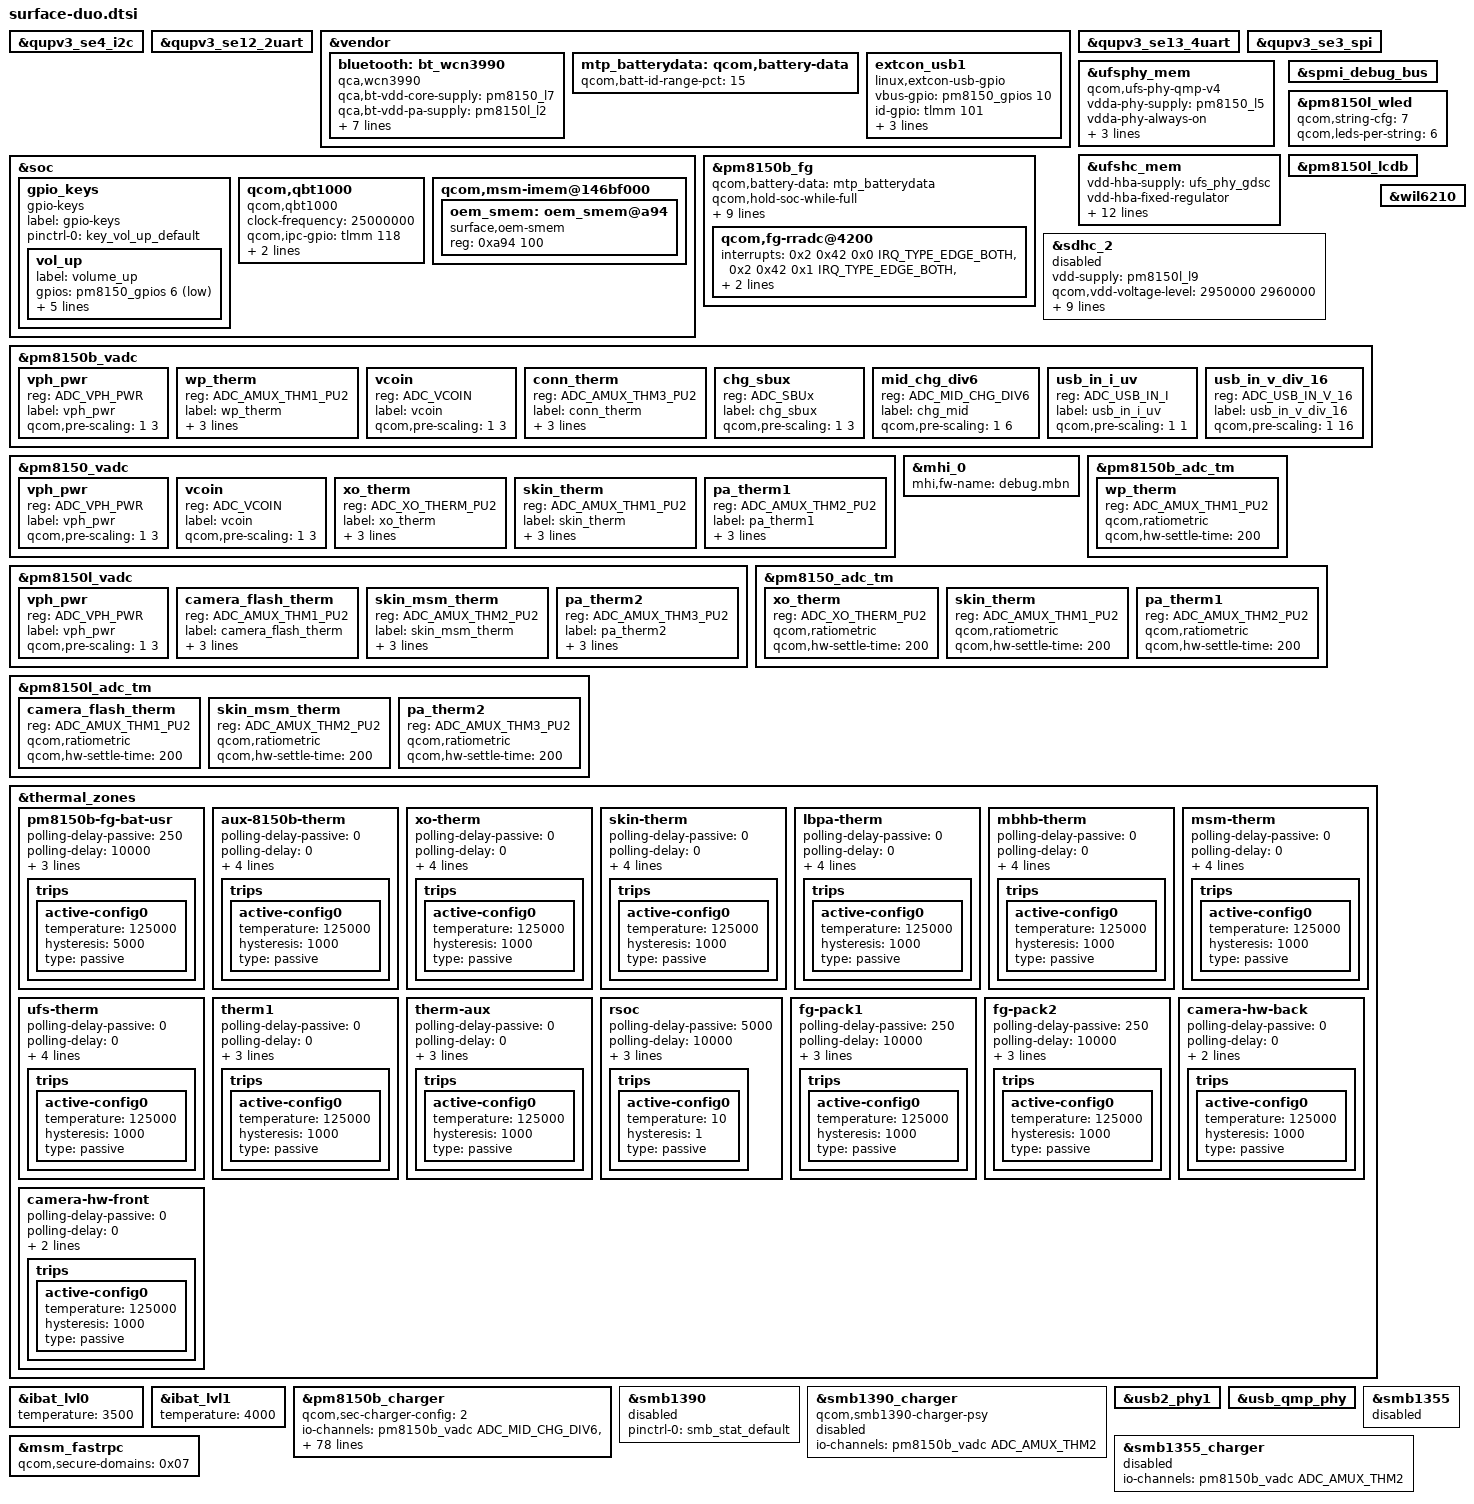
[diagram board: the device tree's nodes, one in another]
/*
 * Copyright (c) 2020 Microsoft Corporation
 *
 * This program is free software; you can redistribute it and/or modify it
 * under the terms of the GNU General Public License version 2 as published by
 * the Free Software Foundation.
 */

#include <dt-bindings/gpio/gpio.h>
#include <dt-bindings/input/input.h>

#include "../qcom/sm8150-pmic-overlay.dtsi"
//#include "../qcom/sm8150-sde-display.dtsi"
#include "surface-duo-display.dtsi"
#include "../qcom/sm8150-thermal-overlay.dtsi"
#include "surface-duo-audio.dtsi"
#include "surface-duo-usb.dtsi"
#include "surface-duo-fpc.dtsi"
#include "surface-duo-touch.dtsi"
#include "surface-duo-fuelgauge.dtsi"
#include "surface-duo-camera-sensor.dtsi"
//#include "surface-duo-powermonitors.dtsi"
#include "da7280.dtsi"
#include "surface-duo-smb138x.dtsi"
#include "surface-duo-pmic-overlay.dtsi"
#include "surface-duo-surface.dtsi"

&qupv3_se4_i2c {
#address-cells = <1>;
#size-cells = <0>;

#include "../qcom/smb1390.dtsi"
#include "../qcom/smb1355.dtsi"
};

&qupv3_se12_2uart {
	status = "ok";
};

&vendor {
	bluetooth: bt_wcn3990 {
		compatible = "qca,wcn3990";
		qca,bt-vdd-core-supply = <&pm8150_l7>;
		qca,bt-vdd-pa-supply = <&pm8150l_l2>;
		qca,bt-vdd-ldo-supply = <&pm8150l_l11>;

		qca,bt-vdd-core-voltage-level = <1800000 1800000>;
		qca,bt-vdd-pa-voltage-level = <1304000 1304000>;
		qca,bt-vdd-ldo-voltage-level = <3312000 3312000>;

		qca,bt-vdd-core-current-level = <0>; /* LPM/PFM */
		qca,bt-vdd-pa-current-level = <0>; /* LPM/PFM */
		qca,bt-vdd-ldo-current-level = <0>; /* LPM/PFM */
	};

	mtp_batterydata: qcom,battery-data {
		qcom,batt-id-range-pct = <15>;
		#include "../qcom/fg-gen4-batterydata-alium-3600mah.dtsi"
	};

	extcon_usb1: extcon_usb1 {
		compatible = "linux,extcon-usb-gpio";
		vbus-gpio = <&pm8150_gpios 10 GPIO_ACTIVE_HIGH>;
		id-gpio = <&tlmm 101 GPIO_ACTIVE_HIGH>;
		vbus-out-gpio = <&pm8150_gpios 9 GPIO_ACTIVE_HIGH>;

		pinctrl-names = "default";
		pinctrl-0 = <&usb2_vbus_det_default
			     &usb2_id_det_default
			     &usb2_vbus_boost_default>;
	};
};

&qupv3_se13_4uart {
	status = "ok";
};

&qupv3_se3_spi {
	status = "ok";
};

&qupv3_se4_i2c {
	status = "ok";
};

&soc {
	gpio_keys {
		compatible = "gpio-keys";
		label = "gpio-keys";

		pinctrl-names = "default";
		pinctrl-0 = <&key_vol_up_default>;

		vol_up {
			label = "volume_up";
			gpios = <&pm8150_gpios 6 GPIO_ACTIVE_LOW>;
			linux,input-type = <1>;
			linux,code = <KEY_VOLUMEUP>;
			gpio-key,wakeup;
			debounce-interval = <15>;
			linux,can-disable;
		};
	};

	qcom,qbt1000 {
		compatible = "qcom,qbt1000";
		clock-names = "core", "iface";
		clock-frequency = <25000000>;
		qcom,ipc-gpio = <&tlmm 118 0>;
		pinctrl-names = "default";
		pinctrl-0 = <&key_home_default>;
		qcom,finger-detect-gpio = <&pm8150_gpios 1 0>;
	};

	qcom,msm-imem@146bf000 {
		oem_smem: oem_smem@a94 {
			compatible = "surface,oem-smem";
			reg = <0xa94 100>;
		};
	};
};
/*
&dsi_sharp_4k_dsc_cmd {
	qcom,panel-supply-entries = <&dsi_panel_pwr_supply>;
	qcom,mdss-dsi-bl-pmic-control-type = "bl_ctrl_wled";
	qcom,mdss-dsi-bl-min-level = <1>;
	qcom,mdss-dsi-bl-max-level = <4095>;
	qcom,mdss-dsi-mode-sel-gpio-state = "dual_port";
	qcom,panel-mode-gpio = <&tlmm 7 0>;
	qcom,platform-te-gpio = <&tlmm 8 0>;
	qcom,platform-reset-gpio = <&tlmm 6 0>;
};

&dsi_sharp_4k_dsc_video {
	qcom,panel-supply-entries = <&dsi_panel_pwr_supply>;
	qcom,mdss-dsi-bl-pmic-control-type = "bl_ctrl_wled";
	qcom,mdss-dsi-bl-min-level = <1>;
	qcom,mdss-dsi-bl-max-level = <4095>;
	qcom,mdss-dsi-mode-sel-gpio-state = "dual_port";
	qcom,panel-mode-gpio = <&tlmm 7 0>;
	qcom,platform-te-gpio = <&tlmm 8 0>;
	qcom,platform-reset-gpio = <&tlmm 6 0>;
};

&dsi_sim_cmd {
	qcom,panel-supply-entries = <&dsi_panel_pwr_supply>;
	qcom,mdss-dsi-bl-pmic-control-type = "bl_ctrl_dcs";
	qcom,platform-reset-gpio = <&tlmm 6 0>;
};

&dsi_sim_vid {
	qcom,panel-supply-entries = <&dsi_panel_pwr_supply>;
	qcom,mdss-dsi-bl-pmic-control-type = "bl_ctrl_dcs";
	qcom,platform-reset-gpio = <&tlmm 6 0>;
};

&dsi_dual_sim_cmd {
	qcom,panel-supply-entries = <&dsi_panel_pwr_supply>;
	qcom,mdss-dsi-bl-pmic-control-type = "bl_ctrl_dcs";
	qcom,platform-reset-gpio = <&tlmm 6 0>;
};

&dsi_dual_sim_vid {
	qcom,panel-supply-entries = <&dsi_panel_pwr_supply>;
	qcom,mdss-dsi-bl-pmic-control-type = "bl_ctrl_dcs";
	qcom,platform-reset-gpio = <&tlmm 6 0>;
};

&dsi_sim_sec_hd_cmd {
	qcom,panel-supply-entries = <&dsi_panel_pwr_supply>;
	qcom,panel-sec-supply-entries = <&dsi_panel_pwr_supply_vdd_no_labibb>;
	qcom,mdss-dsi-bl-pmic-control-type = "bl_ctrl_wled";
	qcom,mdss-dsi-bl-min-level = <1>;
	qcom,mdss-dsi-bl-max-level = <4095>;
	qcom,mdss-dsi-mode-sel-gpio-state = "single_port";
	qcom,panel-mode-gpio = <&tlmm 7 0>;
	qcom,platform-reset-gpio = <&tlmm 6 0>;
	qcom,panel-sec-mode-gpio = <&tlmm 77 0>;
	qcom,platform-sec-reset-gpio = <&tlmm 66 0>;
};

&dsi_dual_nt35597_truly_video {
	qcom,panel-supply-entries = <&dsi_panel_pwr_supply>;
	qcom,mdss-dsi-bl-pmic-control-type = "bl_ctrl_wled";
	qcom,mdss-dsi-bl-min-level = <1>;
	qcom,mdss-dsi-bl-max-level = <4095>;
	qcom,mdss-dsi-mode-sel-gpio-state = "dual_port";
	qcom,panel-mode-gpio = <&tlmm 7 0>;
	qcom,platform-te-gpio = <&tlmm 8 0>;
	qcom,platform-reset-gpio = <&tlmm 6 0>;
};

&dsi_dual_nt35597_truly_cmd {
	qcom,panel-supply-entries = <&dsi_panel_pwr_supply>;
	qcom,mdss-dsi-bl-pmic-control-type = "bl_ctrl_wled";
	qcom,mdss-dsi-bl-min-level = <1>;
	qcom,mdss-dsi-bl-max-level = <4095>;
	qcom,mdss-dsi-mode-sel-gpio-state = "dual_port";
	qcom,panel-mode-gpio = <&tlmm 7 0>;
	qcom,platform-te-gpio = <&tlmm 8 0>;
	qcom,platform-reset-gpio = <&tlmm 6 0>;
};

&dsi_sim_dsc_375_cmd {
	qcom,panel-supply-entries = <&dsi_panel_pwr_supply>;
	qcom,mdss-dsi-bl-pmic-control-type = "bl_ctrl_dcs";
	qcom,platform-reset-gpio = <&tlmm 6 0>;
};

&dsi_dual_sim_dsc_375_cmd {
	qcom,panel-supply-entries = <&dsi_panel_pwr_supply>;
	qcom,mdss-dsi-bl-pmic-control-type = "bl_ctrl_dcs";
	qcom,platform-reset-gpio = <&tlmm 6 0>;
};

&dsi_nt35597_truly_dsc_cmd {
	qcom,panel-supply-entries = <&dsi_panel_pwr_supply>;
	qcom,mdss-dsi-bl-pmic-control-type = "bl_ctrl_wled";
	qcom,mdss-dsi-bl-min-level = <1>;
	qcom,mdss-dsi-bl-max-level = <4095>;
	qcom,mdss-dsi-mode-sel-gpio-state = "single_port";
	qcom,panel-mode-gpio = <&tlmm 7 0>;
	qcom,platform-te-gpio = <&tlmm 8 0>;
	qcom,platform-reset-gpio = <&tlmm 6 0>;
};

&dsi_nt35597_truly_dsc_video {
	qcom,panel-supply-entries = <&dsi_panel_pwr_supply>;
	qcom,mdss-dsi-bl-pmic-control-type = "bl_ctrl_wled";
	qcom,mdss-dsi-bl-min-level = <1>;
	qcom,mdss-dsi-bl-max-level = <4095>;
	qcom,mdss-dsi-mode-sel-gpio-state = "single_port";
	qcom,panel-mode-gpio = <&tlmm 7 0>;
	qcom,platform-te-gpio = <&tlmm 8 0>;
	qcom,platform-reset-gpio = <&tlmm 6 0>;
};

&dsi_nt35695b_truly_fhd_cmd {
	qcom,panel-supply-entries = <&dsi_panel_pwr_supply>;
	qcom,mdss-dsi-bl-pmic-control-type = "bl_ctrl_wled";
	qcom,mdss-dsi-bl-min-level = <1>;
	qcom,mdss-dsi-bl-max-level = <4095>;
	qcom,mdss-dsi-mode-sel-gpio-state = "single_port";
	qcom,panel-mode-gpio = <&tlmm 7 0>;
	qcom,platform-te-gpio = <&tlmm 8 0>;
	qcom,platform-reset-gpio = <&tlmm 6 0>;
};

&dsi_nt35695b_truly_fhd_video {
	qcom,panel-supply-entries = <&dsi_panel_pwr_supply>;
	qcom,mdss-dsi-bl-pmic-control-type = "bl_ctrl_wled";
	qcom,mdss-dsi-bl-min-level = <1>;
	qcom,mdss-dsi-bl-max-level = <4095>;
	qcom,mdss-dsi-mode-sel-gpio-state = "single_port";
	qcom,panel-mode-gpio = <&tlmm 7 0>;
	qcom,platform-te-gpio = <&tlmm 8 0>;
	qcom,platform-reset-gpio = <&tlmm 6 0>;
};*/

&ufsphy_mem {
	compatible = "qcom,ufs-phy-qmp-v4";

	vdda-phy-supply = <&pm8150_l5>;
	vdda-phy-always-on;
	vdda-pll-supply = <&pm8150l_l3>;
	vdda-phy-max-microamp = <90200>;
	vdda-pll-max-microamp = <19000>;

	status = "ok";
};

&ufshc_mem {
	vdd-hba-supply = <&ufs_phy_gdsc>;
	vdd-hba-fixed-regulator;
	vcc-supply = <&pm8150_l10>;
	vcc-voltage-level = <2504000 2950000>;
	vcc-low-voltage-sup;
	vccq-supply = <&pm8150_l9>;
	vccq2-supply = <&pm8150_s4>;
	vcc-max-microamp = <750000>;
	vccq-max-microamp = <700000>;
	vccq2-max-microamp = <750000>;

	qcom,vddp-ref-clk-supply = <&pm8150_l9>;
	qcom,vddp-ref-clk-max-microamp = <100>;
	qcom,vccq-parent-supply = <&pm8150l_s8>;
	qcom,vccq-parent-max-microamp = <210000>;

	status = "ok";
};

&spmi_debug_bus {
	status = "ok";
};

&pm8150l_wled {
	qcom,string-cfg= <7>;
	qcom,leds-per-string = <6>;
	status = "ok";
};

&pm8150l_lcdb {
	status = "ok";
};

&pm8150b_fg {
	qcom,battery-data = <&mtp_batterydata>;
	qcom,hold-soc-while-full;
	qcom,linearize-soc;
	qcom,five-pin-battery;
	qcom,cl-wt-enable;
	/* ESR fast calibration */
	qcom,fg-esr-timer-chg-fast = <0 7>;
	qcom,fg-esr-timer-dischg-fast = <0 7>;
	qcom,fg-esr-timer-chg-slow = <0 96>;
	qcom,fg-esr-timer-dischg-slow = <0 96>;
	qcom,fg-esr-cal-soc-thresh = <26 230>;
	qcom,fg-esr-cal-temp-thresh = <10 40>;

	qcom,fg-rradc@4200 {
		/* Disable Batt-Temp-delta Interrupt */
		interrupts = <0x2 0x42 0x0 IRQ_TYPE_EDGE_BOTH>,
			     <0x2 0x42 0x1 IRQ_TYPE_EDGE_BOTH>,
			     <0x2 0x42 0x3 IRQ_TYPE_EDGE_BOTH>,
			     <0x2 0x42 0x4 IRQ_TYPE_EDGE_BOTH>;
		interrupt-names = "batt-missing",
				  "batt-id",
				  "batt-temp-hot",
				  "batt-temp-cold";
	};
};

&sdhc_2 {
	vdd-supply = <&pm8150l_l9>;
	qcom,vdd-voltage-level = <2950000 2960000>;
	qcom,vdd-current-level = <200 800000>;

	vdd-io-supply = <&pm8150l_l6>;
	qcom,vdd-io-voltage-level = <1808000 2960000>;
	qcom,vdd-io-current-level = <200 22000>;

	pinctrl-names = "active", "sleep";
	pinctrl-0 = <&sdc2_clk_on  &sdc2_cmd_on &sdc2_data_on &storage_cd>;
	pinctrl-1 = <&sdc2_clk_off &sdc2_cmd_off &sdc2_data_off &storage_cd>;

	cd-gpios = <&tlmm 96 GPIO_ACTIVE_LOW>;

	status = "disabled";
};

&pm8150b_vadc {
	vph_pwr {
		reg = <ADC_VPH_PWR>;
		label = "vph_pwr";
		qcom,pre-scaling = <1 3>;
	};

	wp_therm {
		reg = <ADC_AMUX_THM1_PU2>;
		label = "wp_therm";
		qcom,ratiometric;
		qcom,hw-settle-time = <200>;
		qcom,pre-scaling = <1 1>;
	};

	vcoin {
		reg = <ADC_VCOIN>;
		label = "vcoin";
		qcom,pre-scaling = <1 3>;
	};

	conn_therm {
		reg = <ADC_AMUX_THM3_PU2>;
		label = "conn_therm";
		qcom,ratiometric;
		qcom,hw-settle-time = <200>;
		qcom,pre-scaling = <1 1>;
	};

	chg_sbux {
		reg = <ADC_SBUx>;
		label = "chg_sbux";
		qcom,pre-scaling = <1 3>;
	};

	mid_chg_div6 {
		reg = <ADC_MID_CHG_DIV6>;
		label = "chg_mid";
		qcom,pre-scaling = <1 6>;
	};

	usb_in_i_uv {
		reg = <ADC_USB_IN_I>;
		label = "usb_in_i_uv";
		qcom,pre-scaling = <1 1>;
	};

	usb_in_v_div_16 {
		reg = <ADC_USB_IN_V_16>;
		label = "usb_in_v_div_16";
		qcom,pre-scaling = <1 16>;
	};
};

&pm8150_vadc {
	vph_pwr {
		reg = <ADC_VPH_PWR>;
		label = "vph_pwr";
		qcom,pre-scaling = <1 3>;
	};

	vcoin {
		reg = <ADC_VCOIN>;
		label = "vcoin";
		qcom,pre-scaling = <1 3>;
	};

	xo_therm {
		reg = <ADC_XO_THERM_PU2>;
		label = "xo_therm";
		qcom,ratiometric;
		qcom,hw-settle-time = <200>;
		qcom,pre-scaling = <1 1>;
	};

	skin_therm {
		reg = <ADC_AMUX_THM1_PU2>;
		label = "skin_therm";
		qcom,ratiometric;
		qcom,hw-settle-time = <200>;
		qcom,pre-scaling = <1 1>;
	};

	pa_therm1 {
		reg = <ADC_AMUX_THM2_PU2>;
		label = "pa_therm1";
		qcom,ratiometric;
		qcom,hw-settle-time = <200>;
		qcom,pre-scaling = <1 1>;
	};
};

&pm8150l_vadc {
	vph_pwr {
		reg = <ADC_VPH_PWR>;
		label = "vph_pwr";
		qcom,pre-scaling = <1 3>;
	};

	camera_flash_therm {
		reg = <ADC_AMUX_THM1_PU2>;
		label = "camera_flash_therm";
		qcom,ratiometric;
		qcom,hw-settle-time = <200>;
		qcom,pre-scaling = <1 1>;
	};

	skin_msm_therm {
		reg = <ADC_AMUX_THM2_PU2>;
		label = "skin_msm_therm";
		qcom,ratiometric;
		qcom,hw-settle-time = <200>;
		qcom,pre-scaling = <1 1>;
	};

	pa_therm2 {
		reg = <ADC_AMUX_THM3_PU2>;
		label = "pa_therm2";
		qcom,ratiometric;
		qcom,hw-settle-time = <200>;
		qcom,pre-scaling = <1 1>;
	};
};

&wil6210 {
	status = "ok";
};

&mhi_0 {
	mhi,fw-name = "debug.mbn";
};

&pm8150b_adc_tm {
	wp_therm {
		reg = <ADC_AMUX_THM1_PU2>;
		qcom,ratiometric;
		qcom,hw-settle-time = <200>;
	};
};

&pm8150_adc_tm {
	xo_therm {
		reg = <ADC_XO_THERM_PU2>;
		qcom,ratiometric;
		qcom,hw-settle-time = <200>;
	};

	skin_therm {
		reg = <ADC_AMUX_THM1_PU2>;
		qcom,ratiometric;
		qcom,hw-settle-time = <200>;
	};

	pa_therm1 {
		reg = <ADC_AMUX_THM2_PU2>;
		qcom,ratiometric;
		qcom,hw-settle-time = <200>;
	};
};

&pm8150l_adc_tm {
	camera_flash_therm {
		reg = <ADC_AMUX_THM1_PU2>;
		qcom,ratiometric;
		qcom,hw-settle-time = <200>;
	};

	skin_msm_therm {
		reg = <ADC_AMUX_THM2_PU2>;
		qcom,ratiometric;
		qcom,hw-settle-time = <200>;
	};

	pa_therm2 {
		reg = <ADC_AMUX_THM3_PU2>;
		qcom,ratiometric;
		qcom,hw-settle-time = <200>;
	};
};

&thermal_zones {
	pm8150b-fg-bat-usr {
		polling-delay-passive = <250>;
		polling-delay = <10000>;
		thermal-governor = "user_space";
		thermal-sensors = <&pm8150b_fg>;
		wake-capable-sensor;

		trips {
			active-config0 {
				temperature = <125000>;
				hysteresis = <5000>;
				type = "passive";
			};
		};
	};

	aux-8150b-therm {
		polling-delay-passive = <0>;
		polling-delay = <0>;
		thermal-governor = "user_space";
		thermal-sensors = <&pm8150b_adc_tm ADC_AMUX_THM1_PU2>;
		wake-capable-sensor;
		trips {
			active-config0 {
				temperature = <125000>;
				hysteresis = <1000>;
				type = "passive";
			};
		};
	};

	xo-therm {
		polling-delay-passive = <0>;
		polling-delay = <0>;
		thermal-governor = "user_space";
		thermal-sensors = <&pm8150_adc_tm ADC_XO_THERM_PU2>;
		wake-capable-sensor;
		trips {
			active-config0 {
				temperature = <125000>;
				hysteresis = <1000>;
				type = "passive";
			};
		};
	};

	skin-therm {
		polling-delay-passive = <0>;
		polling-delay = <0>;
		thermal-governor = "user_space";
		thermal-sensors = <&pm8150_adc_tm ADC_AMUX_THM1_PU2>;
		wake-capable-sensor;
		trips {
			active-config0 {
				temperature = <125000>;
				hysteresis = <1000>;
				type = "passive";
			};
		};
	};

	lbpa-therm {
		polling-delay-passive = <0>;
		polling-delay = <0>;
		thermal-governor = "user_space";
		thermal-sensors = <&pm8150_adc_tm ADC_AMUX_THM2_PU2>;
		wake-capable-sensor;
		trips {
			active-config0 {
				temperature = <125000>;
				hysteresis = <1000>;
				type = "passive";
			};
		};
	};

	mbhb-therm {
		polling-delay-passive = <0>;
		polling-delay = <0>;
		thermal-governor = "user_space";
		thermal-sensors = <&pm8150l_adc_tm ADC_AMUX_THM1_PU2>;
		wake-capable-sensor;
		trips {
			active-config0 {
				temperature = <125000>;
				hysteresis = <1000>;
				type = "passive";
			};
		};
	};

	msm-therm {
		polling-delay-passive = <0>;
		polling-delay = <0>;
		thermal-governor = "user_space";
		thermal-sensors = <&pm8150l_adc_tm ADC_AMUX_THM2_PU2>;
		wake-capable-sensor;
		trips {
			active-config0 {
				temperature = <125000>;
				hysteresis = <1000>;
				type = "passive";
			};
		};
	};

	ufs-therm {
		polling-delay-passive = <0>;
		polling-delay = <0>;
		thermal-governor = "user_space";
		thermal-sensors = <&pm8150l_adc_tm ADC_AMUX_THM3_PU2>;
		wake-capable-sensor;
		trips {
			active-config0 {
				temperature = <125000>;
				hysteresis = <1000>;
				type = "passive";
			};
		};
	};

	therm1 {
		polling-delay-passive = <0>;
		polling-delay = <0>;
		thermal-governor = "user_space";
		thermal-sensors = <&smb1381_charger 0>;
		wake-capable-sensor;
		trips {
			active-config0 {
				temperature = <125000>;
				hysteresis = <1000>;
				type = "passive";
			};
		};
	};

	therm-aux {
		polling-delay-passive = <0>;
		polling-delay = <0>;
		thermal-governor = "user_space";
		thermal-sensors = <&smb1381_charger 1>;
		wake-capable-sensor;
		trips {
			active-config0 {
				temperature = <125000>;
				hysteresis = <1000>;
				type = "passive";
			};
		};
	};

	rsoc {
		polling-delay-passive = <5000>;
		polling-delay = <10000>;
		thermal-governor = "user_space";
		thermal-sensors = <&bcl_soc>;
		tracks-low;

		trips {
			active-config0 {
				temperature = <10>;
				hysteresis = <1>;
				type = "passive";
			};
		};
	};

	fg-pack1 {
		polling-delay-passive = <250>;
		polling-delay = <10000>;
		thermal-governor = "user_space";
		thermal-sensors = <&fuel_gauge_pack1>;
		wake-capable-sensor;
		trips {
			active-config0 {
				temperature = <125000>;
				hysteresis = <1000>;
				type = "passive";
			};
		};
	};

	fg-pack2 {
		polling-delay-passive = <250>;
		polling-delay = <10000>;
		thermal-governor = "user_space";
		thermal-sensors = <&fuel_gauge_pack2>;
		wake-capable-sensor;
		trips {
			active-config0 {
				temperature = <125000>;
				hysteresis = <1000>;
				type = "passive";
			};
		};
	};

	camera-hw-back {
		polling-delay-passive = <0>;
		polling-delay = <0>;
		thermal-governor = "user_space";
		thermal-sensors = <&cam_sensor0>;
		trips {
			active-config0 {
				temperature = <125000>;
				hysteresis = <1000>;
				type = "passive";
			};
		};
	};

	camera-hw-front {
		polling-delay-passive = <0>;
		polling-delay = <0>;
		thermal-governor = "user_space";
		thermal-sensors = <&cam_sensor1>;
		trips {
			active-config0 {
				temperature = <125000>;
				hysteresis = <1000>;
				type = "passive";
			};
		};
	};
};

&ibat_lvl0 {
	temperature = <3500>;
};

&ibat_lvl1 {
	temperature = <4000>;
};

&pm8150b_charger {
	qcom,sec-charger-config = <2>;
	io-channels = <&pm8150b_vadc ADC_MID_CHG_DIV6>,
		      <&pm8150b_vadc ADC_USB_IN_I>,
		      <&pm8150b_vadc ADC_SBUx>,
		      <&pm8150b_vadc ADC_VPH_PWR>,
		      <&pm8150b_vadc ADC_CHG_TEMP>,
		      <&pm8150b_vadc ADC_USB_IN_V_16>;
	io-channel-names = "mid_voltage",
			   "usb_in_current",
			   "sbux_res",
			   "vph_voltage",
			   "chg_temp",
			   "usb_in_voltage";
	qcom,battery-data = <&mtp_batterydata>;
	qcom,step-charging-enable;
	qcom,sw-jeita-enable;
	qcom,wd-bark-time-secs = <16>;
	qcom,suspend-input-on-debug-batt;
	qcom,fcc-max-ua = <3703000>;
	qcom,fv-max-uv = <4400000>;
	qcom,usb-icl-ua = <3000000>;
	qcom,thermal-mitigation = <3703000 1852000 741000 185000>;
	qcom,hvdcp-disable;
	qcom,otg-cl-ua = <1000000>;

	ms,num-gpio = <8>;
	ms,pmicgpios = <&pm8150l_gpios 8 GPIO_ACTIVE_HIGH>,  /* CELL_PACK1_DISC */
			<&pm8150l_gpios 5 GPIO_ACTIVE_HIGH>,			/* CELL_PACK2_DISC */
			<&pm8150l_gpios 11 GPIO_ACTIVE_LOW>,			/* BYPASS_SHDN_N */
			<&pm8150l_gpios 10 GPIO_ACTIVE_HIGH>,			/* RSHARE_CTRL */
			<&pm8150l_gpios 1 GPIO_ACTIVE_HIGH>,			/* VREF_CTRL_1 */
			<&pm8150l_gpios 2 GPIO_ACTIVE_HIGH>,			/* VREF_CTRL_2 */
			<&pm8150l_gpios 3 GPIO_ACTIVE_HIGH>,			/* VREF_CTRL_3 */
			<&pm8150l_gpios 4 GPIO_ACTIVE_HIGH>;			/* VREF_CTRL_4 */
	ms,fuel-gauges = "bq27742-1", "bq27742-0";
	ms,vdelta = <100>;		//mV
	ms,socdelta = <10>; 		//%
	ms,socdeltamax = <10>;	//%
	ms,socdeltahys = <5>;	//%
	ms,numpacks = <2>;		//number of packs
	ms,floatvoltageHHL = <4200000>; //uV
	ms,pack1-fcc = <803>;
	ms,pack1-cp1chargerate = <100>;
	ms,pack1-cp2chargerate = <70>;
	ms,pack1-cp3chargerate = <50>;
	ms,pack2-fcc = <2900>;
	ms,pack2-cp1chargerate = <100>;
	ms,pack2-cp2chargerate = <70>;
	ms,pack2-cp3chargerate = <50>;
	ms,soccheckpoint1 = <50>;
	ms,soccheckpoint2 = <80>;
	ms,soccheckpoint3 = <100>;

	ms,pack1-extremecoldlimit = <0>;  // deciC
	ms,pack1-hardcoldlimit = <150>;
	ms,pack1-softcoldlimit = <250>;
	ms,pack1-softhotlimit = <350>;
	ms,pack1-hardhotlimit = <450>;
	ms,pack1-extremehotlimit = <600>;
	ms,pack1-temphyst = <10>;
	ms,pack1-chargerateHCL = <20>;  // %
	ms,pack1-chargerateSCLandcp1 = <70>;
	ms,pack1-chargerateSCLandcp2 = <50>;
	ms,pack1-chargerateSCLandcp3 = <30>;
	ms,pack1-chargerateSHLandcp1 = <70>;
	ms,pack1-chargerateHHL = <25>;

	ms,pack2-extremecoldlimit = <0>;  // deciC
	ms,pack2-hardcoldlimit = <150>;
	ms,pack2-softcoldlimit = <250>;
	ms,pack2-softhotlimit = <350>;
	ms,pack2-hardhotlimit = <450>;
	ms,pack2-extremehotlimit = <600>;
	ms,pack2-temphyst = <10>;
	ms,pack2-chargerateHCL = <20>;  // %
	ms,pack2-chargerateSCLandcp1 = <70>;
	ms,pack2-chargerateSCLandcp2 = <50>;
	ms,pack2-chargerateSCLandcp3 = <30>;
	ms,pack2-chargerateSHLandcp1 = <70>;
	ms,pack2-chargerateHHL = <25>;

	ms,psu-heartbeat-timer = <1000>; // 1 sec
	ms,batt-heartbeat-timer = <30000>; // 30 secs

	ms,auto-recharge-soc = <95>;

	// telemetry static information;
	ms,hvt-temp-bucket-low = <210>; // in deci C
	ms,hvt-temp-bucket-mid = <360>;
	ms,hvt-temp-bucket-high = <450>;

	ms,hvt-rsoc-buckets = <49 79 89 94 100>; // array of rsoc %

};

&smb1390 {
	pinctrl-names = "default";
	pinctrl-0 = <&smb_stat_default>;
	status = "disabled";
};

&smb1390_charger {
	/delete-property/ compatible;
	compatible = "qcom,smb1390-charger-psy";
	io-channels = <&pm8150b_vadc ADC_AMUX_THM2>;
	io-channel-names = "cp_die_temp";
	status = "disabled";
};

/* &usb1 {
	extcon = <&extcon_usb1>;
	status = "ok";
};*/

&usb2_phy1 {
	status = "ok";
};

&usb_qmp_phy {
	status = "ok";
};

&smb1355 {
	status = "disabled";
};

&smb1355_charger {
	io-channels = <&pm8150b_vadc ADC_AMUX_THM2>;
	io-channel-names = "charger_temp";
	status = "disabled";
};

&msm_fastrpc {
	qcom,secure-domains = <0x07>;
};
